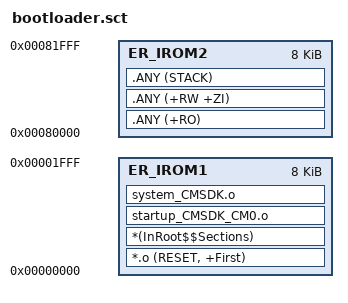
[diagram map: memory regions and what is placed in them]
; *************************************************************
; *** Scatter-Loading Description File generated by uVision ***
; *************************************************************

LR_IROM1 0x00000000 0x00008000  {    ; load region size_region
  ER_IROM1 0x00000000 0x00002000  {  ; load address = execution address
   *.o (RESET, +First)
   *(InRoot$$Sections)
   startup_CMSDK_CM0.o
   system_CMSDK.o
  }
;  }
;  LR_IROM2 0x80000 0x2000 {
;RW_IRAM15 0x00080000 0x00000700 {  ; RW data
 ;  .ANY (STACK)
 ; }

ER_IROM2 0x80000 0x2000 {
     .ANY (+RO)
   .ANY (+RW +ZI)
   .ANY (STACK)
  }
}

